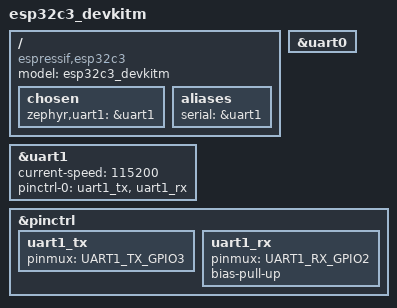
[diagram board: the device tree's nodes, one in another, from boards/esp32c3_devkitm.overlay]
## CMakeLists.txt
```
# SPDX-License-Identifier: Apache-2.0

# Setting Minimum CMake version
cmake_minimum_required(VERSION 3.20.0)

# Setting board to the ESP32 - C3
set(BOARD esp32c3_devkitm)

# Finding the Zephyr Base Package
find_package(Zephyr REQUIRED HINTS $ENV{ZEPHYR_BASE})

# Initialising project as Prac 1
project(prac1)

# Setting CMAKE Relative Directory
set(CMAKE_DIR ~/csse4011/repo/prac1/ahu)

# Setting Global app_sources as relative to ahu -> ahu/src/
FILE(GLOB app_sources ${CMAKE_DIR}/src/*.c)

# Setting Target Source for app under app sources
target_sources(app PRIVATE ${app_sources})

# Setting required directories
set(REPO_DIR            ~/csse4011/repo/)               # REPOSITORY ~/csse4011/repo
set(PRAC_ONE_DIR        ${REPO_DIR}/prac1)              # PRAC ONE ~/csse4011/repo/prac1
set(AHU_SRC_DIR         ${PRAC_ONE_DIR}/ahu/src/)       # AHU SOURCE ~/csse4011/repo/prac1/ahu/src/
set(OSLIB_DIR           ${REPO_DIR}/oslib/)             # OSLIB ~/csse4011/repo/oslib/
set(AHU_DRIVERS_DIR     ${OSLIB_DIR}/ahu_drivers)       # AHU DRIVERS ~/csse4011/repo/oslib/ahu_drivers/
set(AHU_HCI_SRC_DIR     ${AHU_DRIVERS_DIR}/ahu_hci/)    # AHU HCI SRC ~/csse4011/repo/oslib/ahu_drivers/ahu_hci/

# Including target sources as private
target_include_directories(app PRIVATE 
  ${REPO_DIR}
  ${PRAC_ONE_DIR}
  ${AHU_SRC_DIR}
  ${OSLIB_DIR}
  ${AHU_DRIVERS_DIR}
  ${AHU_HCI_SRC_DIR}
)

target_sources(app PRIVATE 
  ${AHU_HCI_SRC_DIR}/shell_cli.c      # Including SHELL Command Line Interface (cli)
  ${AHU_HCI_SRC_DIR}/ahu_hci.c        # Including SHELL Command Line Interface (cli)
  ${AHU_HCI_SRC_DIR}/ahu_uart.c       # Including UART Host Controller Interface (HCI)
  ${AHU_SRC_DIR}/main.c               # Including main.c
)
```

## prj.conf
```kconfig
CONFIG_GPIO=y
CONFIG_PRINTK=y
CONFIG_CBPRINTF_FP_SUPPORT=y

#-----------------------------SHELL_CONF--------------------------------------
CONFIG_UART_LINE_CTRL=y
CONFIG_SHELL=y
CONFIG_SHELL_PROMPT_UART="Team 1 - CSSE4011:~$ "
CONFIG_SHELL_CMDS=y
CONFIG_SHELL_TAB=y
CONFIG_SHELL_TAB_AUTOCOMPLETION=y
CONFIG_SHELL_VT100_COLORS=y

#-----------------------------SHELL_LOGGING-----------------------------------
CONFIG_LOG=y
CONFIG_LOG_PRINTK=y
CONFIG_LOG_BUFFER_SIZE=1024
CONFIG_LOG_OVERRIDE_LEVEL=3
#------------------------------OTHER_CONFIGS----------------------------------

CONFIG_INIT_STACKS=y
CONFIG_THREAD_STACK_INFO=y
CONFIG_KERNEL_SHELL=y
CONFIG_THREAD_MONITOR=y
CONFIG_BOOT_BANNER=n
CONFIG_THREAD_NAME=y
CONFIG_DEVICE_SHELL=y
CONFIG_POSIX_CLOCK=y
CONFIG_DATE_SHELL=y
CONFIG_THREAD_RUNTIME_STATS=y
CONFIG_THREAD_RUNTIME_STATS_USE_TIMING_FUNCTIONS=y
CONFIG_STATS=y
CONFIG_STATS_SHELL=y
# CONFIG_STDOUT_CONSOLE=y
# CONFIG_LED_STRIP=y
# CONFIG_LED_STRIP_LOG_LEVEL_DBG=y
# CONFIG_WS2812_STRIP=y
CONFIG_HEAP_MEM_POOL_SIZE=256
CONFIG_SERIAL=y
CONFIG_CONSOLE=y
CONFIG_UART_CONSOLE=y
# CONFIG_UART_LINE_CTRL=y
CONFIG_UART_INTERRUPT_DRIVEN=y
```

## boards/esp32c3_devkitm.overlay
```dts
#include <espressif/esp32c3.dtsi>
#include <zephyr/dt-bindings/pinctrl/esp-pinctrl-common.h>
#include <dt-bindings/pinctrl/esp32c3-pinctrl.h>
#include <zephyr/dt-bindings/pinctrl/esp32c3-gpio-sigmap.h>

/ {
    model = "esp32c3_devkitm";
	compatible = "espressif,esp32c3";

    chosen {
        zephyr,uart1 = &uart1;
    };

    aliases {
        serial = &uart1;
    };
};

&uart0 {
    status ="okay";
};

&uart1 {
    status = "okay";
    current-speed = <115200>;
    pinctrl-0 = <&uart1_tx &uart1_rx>;
    pinctrl-names = "default";
};

&pinctrl {
    uart1_tx: uart1_tx {
        pinmux = <UART1_TX_GPIO3>;
    };

    uart1_rx: uart1_rx {
        pinmux = <UART1_RX_GPIO2>;
        bias-pull-up;
    };
};
```

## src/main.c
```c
/* Standard Includes */
#include <stdio.h>
#include <stdlib.h>

/* Zephyr Includes */
#include <zephyr/shell/shell.h>
#include <zephyr/shell/shell_uart.h>
#include <zephyr/drivers/pwm.h>
#include <zephyr/drivers/uart.h>
#include <zephyr/drivers/gpio.h>
#include <zephyr/device.h>
#include <zephyr/kernel.h>

/* Local Source Includes */
#include "shell_cli.h"
#include "ahu_hci.h"
#include "ahu_uart.h"

// void main(void) {}
```
